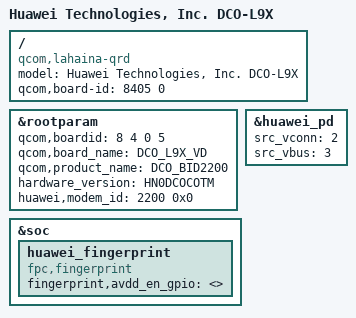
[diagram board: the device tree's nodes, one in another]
/dts-v1/;
/plugin/;

#include "../common/common.dtsi"
#include "huawei-nfc.dtsi"
#include "huawei_camera.dtsi"
#include "huawei_wifi.dtsi"
#include "huawei_fac.dtsi"
#include "huawei-bt.dtsi"

/ {
    /* bsp_replace_info @ model = "Huawei Technologies, Inc. %product_name%"; */
    model = "Huawei Technologies, Inc. DCO-L9X";
    compatible = "qcom,lahaina-qrd", "qcom,lahaina", "qcom,qrd";
    /* bsp_replace_info @ qcom,board-id = <%boardid% 0>; */
    qcom,board-id = <8405 0>;
};

&rootparam {
    /* bsp_replace_info @ qcom,boardid = <%boardid_split%>; */
    /* auto_key_info @ name: boardid type: uint32 default: 0 */
    qcom,boardid = <8 4 0 5>;
    /* bsp_replace_info @ qcom,board_name = "%board_name%"; */
    qcom,board_name = "DCO_L9X_VD";
    /* bsp_replace_info @ qcom,product_name = "%product_name%"; */
    qcom,product_name = "DCO_BID2200";
    /* bsp_replace_info @ hardware_version = "%hardware_version%"; */
    hardware_version = "HN0DCOCOTM";
    /* bsp_replace_info @ huawei,modem_id = <%modem_id% 0x0>; */
    huawei,modem_id = <2200 0x0>;
};

&huawei_pd {
	src_vconn = <2>; /* 5v-boost */
	src_vbus = <3>; /* pmic */
};

&soc {
	huawei_fingerprint {
		compatible = "fpc,fingerprint";
		fingerprint,avdd_en_gpio = <>;

		status = "ok";
	};
};
